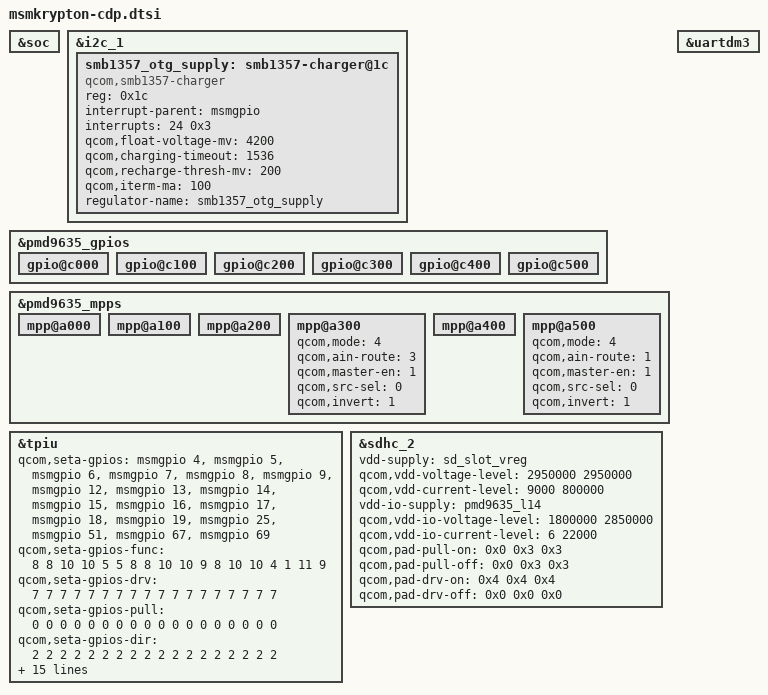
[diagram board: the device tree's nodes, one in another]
/* Copyright (c) 2013, The Linux Foundation. All rights reserved.
 *
 * This program is free software; you can redistribute it and/or modify
 * it under the terms of the GNU General Public License version 2 and
 * only version 2 as published by the Free Software Foundation.
 *
 * This program is distributed in the hope that it will be useful,
 * but WITHOUT ANY WARRANTY; without even the implied warranty of
 * MERCHANTABILITY or FITNESS FOR A PARTICULAR PURPOSE.  See the
 * GNU General Public License for more details.
 */

&soc {
};

&i2c_1 {
	smb1357_otg_supply: smb1357-charger@1c {
		compatible = "qcom,smb1357-charger";
		reg = <0x1c>;
		interrupt-parent = <&msmgpio>;
		interrupts = <24 0x3>;	/* MDM GPIO 24 */
		qcom,float-voltage-mv = <4200>;
		qcom,charging-timeout = <1536>;
		qcom,recharge-thresh-mv = <200>;
		qcom,iterm-ma = <100>;
		regulator-name = "smb1357_otg_supply";
	};
};

&pmd9635_gpios {
	gpio@c000 { /* GPIO 1 */
	};

	gpio@c100 { /* GPIO 2 */
	};

	gpio@c200 { /* GPIO 3 */
	};

	gpio@c300 { /* GPIO 4 */
	};

	gpio@c400 { /* GPIO 5 */
	};

	gpio@c500 { /* GPIO 6 */
	};
};

&pmd9635_mpps {
	mpp@a000 { /* MPP 1 */
	};

	mpp@a100 { /* MPP 2 */
	};

	mpp@a200 { /* MPP 3 */
	};

	mpp@a300 { /* MPP 4 */
		/* VADC channel 19 */
		qcom,mode = <4>;
		qcom,ain-route = <3>; /* AMUX 8 */
		qcom,master-en = <1>;
		qcom,src-sel = <0>; /* Function constant */
		qcom,invert = <1>;
	};

	mpp@a400 { /* MPP 5 */
	};

	mpp@a500 { /* MPP 6 */
		/* channel 21 */
		qcom,mode = <4>;
		qcom,ain-route = <1>; /* AMUX 6 */
		qcom,master-en = <1>;
		qcom,src-sel = <0>; /* Function constant */
		qcom,invert = <1>;
	};
};

&uartdm3{
	status = "ok";
};

/* CoreSight */
&tpiu {
	qcom,seta-gpios = <&msmgpio 4 0>,
			  <&msmgpio 5 0>,
			  <&msmgpio 6 0>,
			  <&msmgpio 7 0>,
			  <&msmgpio 8 0>,
			  <&msmgpio 9 0>,
			  <&msmgpio 12 0>,
			  <&msmgpio 13 0>,
			  <&msmgpio 14 0>,
			  <&msmgpio 15 0>,
			  <&msmgpio 16 0>,
			  <&msmgpio 17 0>,
			  <&msmgpio 18 0>,
			  <&msmgpio 19 0>,
			  <&msmgpio 25 0>,
			  <&msmgpio 51 0>,
			  <&msmgpio 67 0>,
			  <&msmgpio 69 0>;
	qcom,seta-gpios-func = <8 8 10 10 5 5 8 8 10 10 9 8 10 10 4 1 11 9>;
	qcom,seta-gpios-drv =  <7 7 7 7 7 7 7 7 7 7 7 7 7 7 7 7 7 7>;
	qcom,seta-gpios-pull = <0 0 0 0 0 0 0 0 0 0 0 0 0 0 0 0 0 0>;
	qcom,seta-gpios-dir =  <2 2 2 2 2 2 2 2 2 2 2 2 2 2 2 2 2 2>;

	qcom,setb-gpios = <&msmgpio 16 0>,
			  <&msmgpio 17 0>,
			  <&msmgpio 18 0>,
			  <&msmgpio 19 0>,
			  <&msmgpio 25 0>,
			  <&msmgpio 33 0>,
			  <&msmgpio 34 0>,
			  <&msmgpio 36 0>,
			  <&msmgpio 38 0>,
			  <&msmgpio 39 0>,
			  <&msmgpio 50 0>,
			  <&msmgpio 51 0>,
			  <&msmgpio 52 0>,
			  <&msmgpio 53 0>,
			  <&msmgpio 62 0>,
			  <&msmgpio 63 0>,
			  <&msmgpio 67 0>,
			  <&msmgpio 70 0>;
	qcom,setb-gpios-func = <10 9 11 11 5 2 2 3 2 2 2 2 3 3 5 6 12 4>;
	qcom,setb-gpios-drv =  <7 7 7 7 7 7 7 7 7 7 7 7 7 7 7 7 7 7>;
	qcom,setb-gpios-pull = <0 0 0 0 0 0 0 0 0 0 0 0 0 0 0 0 0 0>;
	qcom,setb-gpios-dir =  <2 2 2 2 2 2 2 2 2 2 2 2 2 2 2 2 2 2>;
};

&sdhc_2 {
	vdd-supply = <&sd_slot_vreg>;
	qcom,vdd-voltage-level = <2950000 2950000>;
	qcom,vdd-current-level = <9000 800000>;

	vdd-io-supply = <&pmd9635_l14>;
	qcom,vdd-io-voltage-level = <1800000 2850000>;
	qcom,vdd-io-current-level = <6 22000>;

	qcom,pad-pull-on = <0x0 0x3 0x3>; /* no-pull, pull-up, pull-up */
	qcom,pad-pull-off = <0x0 0x3 0x3>; /* no-pull, pull-up, pull-up */
	qcom,pad-drv-on = <0x4 0x4 0x4>; /* 10mA, 10mA, 10mA */
	qcom,pad-drv-off = <0x0 0x0 0x0>; /* 2mA, 2mA, 2mA */
	status = "ok";
};
